# FM33FK5XX register map
File version: 1.0
CPU: Cortex-M33 r1p0, little endian, MPU, FPU, 3 interrupt priority bits
Registers are 32-bit, read-write, reset 0x0 unless marked. A register's access mark holds for its fields unless they carry their own. Offsets are from the block's base; [hi:lo] are bit positions; {n}, {i} and the like mark numbered series; 'fields as' and 'values as' point back to an identical list.

## EPSC — EPSC module information
Base 0x40001400
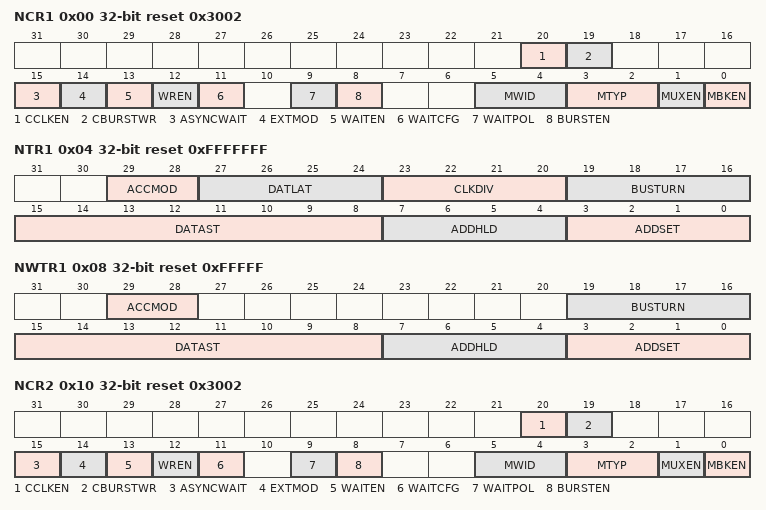
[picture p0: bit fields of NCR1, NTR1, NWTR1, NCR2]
0x00 NCR1 reset 0x3002
  [20] CCLKEN — CCLKEN field description
  [19] CBURSTWR — CBURSTWR field description
  [15] ASYNCWAIT — ASYNCWAIT field description
  [14] EXTMOD — EXTMOD field description
  [13] WAITEN — WAITEN field description
  [12] WREN — WREN field description
  [11] WAITCFG — WAITCFG field description
  [9] WAITPOL — WAITPOL field description
  [8] BURSTEN — BURSTEN field description
  [5:4] MWID — MWID field description
  [3:2] MTYP — MTYP field description
  [1] MUXEN — MUXEN field description
  [0] MBKEN — MBKEN field description
0x04 NTR1 reset 0xFFFFFFF
  [29:28] ACCMOD — ACCMOD field description
  [27:24] DATLAT — DATLAT field description
  [23:20] CLKDIV — CLKDIV field description
  [19:16] BUSTURN — BUSTURN field description
  [15:8] DATAST — DATAST field description
  [7:4] ADDHLD — ADDHLD field description
  [3:0] ADDSET — ADDSET field description
0x08 NWTR1 reset 0xFFFFF
  [29:28] ACCMOD — ACCMOD field description
  [19:16] BUSTURN — BUSTURN field description
  [15:8] DATAST — DATAST field description
  [7:4] ADDHLD — ADDHLD field description
  [3:0] ADDSET — ADDSET field description
0x10 NCR2 reset 0x3002
  fields as NCR1
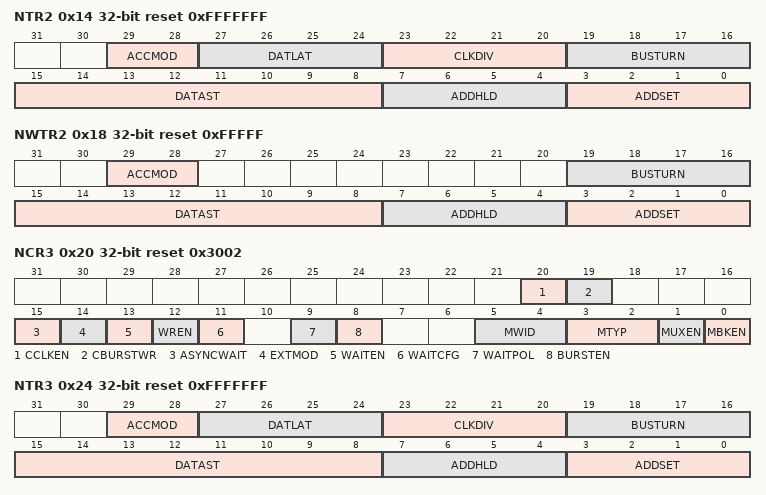
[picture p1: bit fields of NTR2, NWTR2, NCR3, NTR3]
0x14 NTR2 reset 0xFFFFFFF
  fields as NTR1
0x18 NWTR2 reset 0xFFFFF
  fields as NWTR1
0x20 NCR3 reset 0x3002
  fields as NCR1
0x24 NTR3 reset 0xFFFFFFF
  fields as NTR1
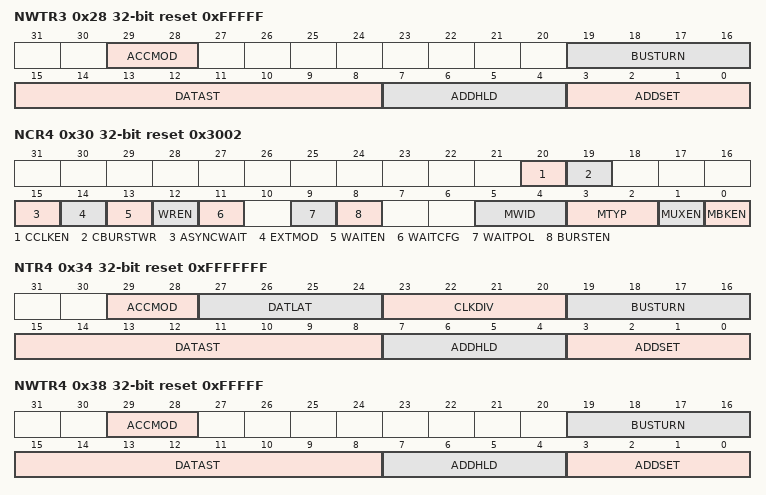
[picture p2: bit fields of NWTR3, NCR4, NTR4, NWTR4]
0x28 NWTR3 reset 0xFFFFF
  fields as NWTR1
0x30 NCR4 reset 0x3002
  fields as NCR1
0x34 NTR4 reset 0xFFFFFFF
  fields as NTR1
0x38 NWTR4 reset 0xFFFFF
  fields as NWTR1
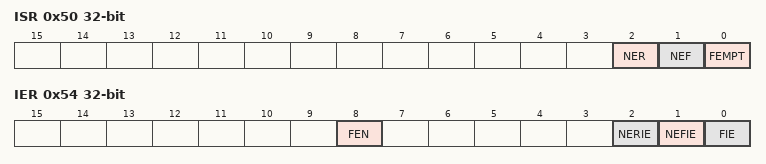
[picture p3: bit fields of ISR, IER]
0x50 ISR access per field
  [2] NER rw — NER field description
  [1] NEF rw — NEF field description
  [0] FEMPT ro — FEMPT field description
0x54 IER
  [8] FEN — FEN field description
  [2] NERIE — NERIE field description
  [1] NEFIE — NEFIE field description
  [0] FIE — FIE field description
0x58 TO reset 0xFF
  [15:0] EPSC_TO — EPSC_TO field description

## DMA — DMA module information
Base 0x40000400
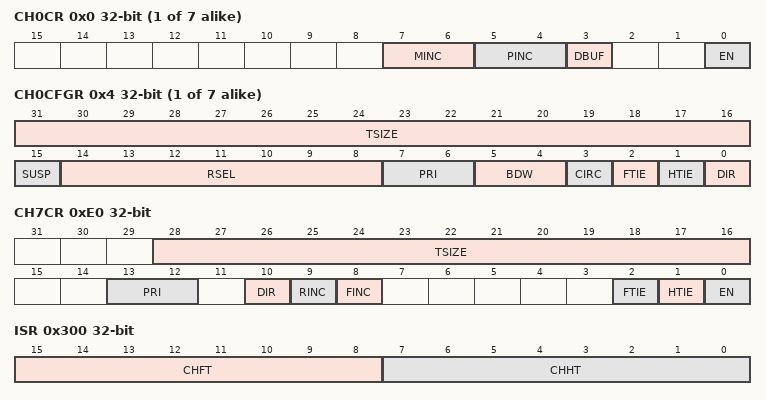
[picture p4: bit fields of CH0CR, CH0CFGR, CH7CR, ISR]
{0x0+0x20*i} CH{i}CR (i=0..6) — Channel{i}ControlRegister
  [7:6] MINC — MINC field description
  [5:4] PINC — PINC field description
  [3] DBUF — DBUF field description
  [0] EN — EN field description
{0x4+0x20*i} CH{i}CFGR (i=0..6) — Channel{i}ConfigRegister
  [31:16] TSIZE — TSIZE field description
  [15] SUSP — SUSP field description
  [14:8] RSEL — RSEL field description
  [7:6] PRI — PRI field description
  [5:4] BDW — BDW field description
  [3] CIRC — CIRC field description
  [2] FTIE — FTIE field description
  [1] HTIE — HTIE field description
  [0] DIR — DIR field description
{0x8+0x20*i} CH{i}PAR (i=0..6) — Channel{i}PeripheralAddressRegister
  [31:0] PAD — PAD field description
{0xC+0x20*i} CH{i}MAR0 (i=0..6) — Channel{i}MemoryAddressRegister0
  [31:0] MAD0 — MAD0 field description
{0x10+0x20*i} CH{i}MAR1 (i=0..6) — Channel{i}MemoryAddressRegister1
  [31:0] MAD1 — MAD1 field description
0xE0 CH7CR — Channel7ControlRegister
  [28:16] TSIZE — TSIZE field description
  [13:12] PRI — PRI field description
  [10] DIR — DIR field description
  [9] RINC — RINC field description
  [8] FINC — FINC field description
  [2] FTIE — FTIE field description
  [1] HTIE — HTIE field description
  [0] EN — EN field description
0xE4 CH7FAR — Channel7FlashAddressRegister
  [15:0] FLSAD — FLSAD field description
0xE8 CH7RAR — Channel7RAMAddressRegister
  [13:0] RAMAD — RAMAD field description
0x200 GCR — DMAGlobalControlRegister
  [0] EN — EN field description
0x204 SWRR — DMASoftwareRequestRegister
  [6:0] SWTRIG — SWTRIG field description
0x300 ISR — DMAInterruptStatusRegister
  [15:8] CHFT — CHFT field description
  [7:0] CHHT — CHHT field description
{0x304+4i} CH{i}TFSADDR ro (i=0..6)
  [15:0] TFSIZE_CNT — TFSIZE_CNT field description
